# ATmega2560 device description
Architecture: AVR8; Family: megaAVR
Registers are 8-bit, access not given, no defined reset value unless marked. A register's access mark holds for its fields unless they carry their own. Offsets are from the block's base; [hi:lo] are bit positions.

## PORTA — I/O Port
Instances: PORTA 0x00
0x20 PINA — Port A Input Pins
0x21 DDRA — Port A Data Direction Register
0x22 PORTA — Port A Data Register

## PORTB — I/O Port
Instances: PORTB 0x00
0x23 PINB — Port B Input Pins
0x24 DDRB — Port B Data Direction Register
0x25 PORTB — Port B Data Register

## PORTC — I/O Port
Instances: PORTC 0x00
0x26 PINC — Port C Input Pins
0x27 DDRC — Port C Data Direction Register
0x28 PORTC — Port C Data Register

## PORTD — I/O Port
Instances: PORTD 0x00
0x29 PIND — Port D Input Pins
0x2A DDRD — Port D Data Direction Register
0x2B PORTD — Port D Data Register

## PORTE — I/O Port
Instances: PORTE 0x00
0x2C PINE — Input Pins, Port E
0x2D DDRE — Data Direction Register, Port E
0x2E PORTE — Data Register, Port E

## PORTF — I/O Port
Instances: PORTF 0x00
0x2F PINF — Input Pins, Port F
0x30 DDRF — Data Direction Register, Port F
0x31 PORTF — Data Register, Port F

## PORTG — I/O Port
Instances: PORTG 0x00
0x32 PING bits used 5:0 — Input Pins, Port G
0x33 DDRG bits used 5:0 — Data Direction Register, Port G
0x34 PORTG bits used 5:0 — Data Register, Port G

## PORTH — I/O Port
Instances: PORTH 0x00
0x100 PINH — PORT H Input Pins
0x101 DDRH — PORT H Data Direction Register
0x102 PORTH — PORT H Data Register

## PORTJ — I/O Port
Instances: PORTJ 0x00
0x103 PINJ — PORT J Input Pins
0x104 DDRJ — PORT J Data Direction Register
0x105 PORTJ — PORT J Data Register

## PORTK — I/O Port
Instances: PORTK 0x00
0x106 PINK — PORT K Input Pins
0x107 DDRK — PORT K Data Direction Register
0x108 PORTK — PORT K Data Register

## PORTL — I/O Port
Instances: PORTL 0x00
0x109 PINL — PORT L Input Pins
0x10A DDRL — PORT L Data Direction Register
0x10B PORTL — PORT L Data Register

## TC0 (TC8 module) — Timer/Counter, 8-bit
Instances: TC0 0x00
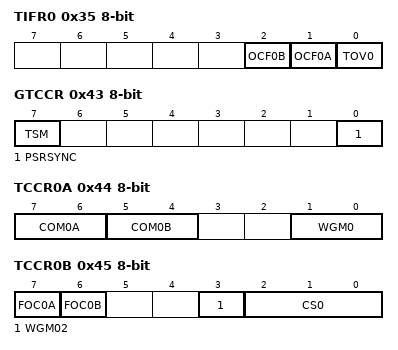
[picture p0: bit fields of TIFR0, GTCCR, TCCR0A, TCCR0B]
0x35 TIFR0 — Timer/Counter0 Interrupt Flag register
  [2] OCF0B — Timer/Counter0 Output Compare Flag 0B
  [1] OCF0A — Timer/Counter0 Output Compare Flag 0A
  [0] TOV0 — Timer/Counter0 Overflow Flag
0x43 GTCCR — General Timer/Counter Control Register
  [7] TSM — Timer/Counter Synchronization Mode
  [0] PSRSYNC — Prescaler Reset Timer/Counter1 and Timer/Counter0
0x44 TCCR0A — Timer/Counter Control Register A
  [7:6] COM0A — Compare Output Mode, Phase Correct PWM Mode
  [5:4] COM0B — Compare Output Mode, Fast PWm
  [1:0] WGM0 — Waveform Generation Mode
0x45 TCCR0B — Timer/Counter Control Register B
  [7] FOC0A — Force Output Compare A
  [6] FOC0B — Force Output Compare B
  [3] WGM02
  [2:0] CS0 — Clock Select
    0=No Clock Source (Stopped); 1=Running, No Prescaling; 2=Running, CLK/8; 3=Running, CLK/64; 4=Running, CLK/256; 5=Running, CLK/1024; 6=Running, ExtClk Tx Falling Edge; 7=Running, ExtClk Tx Rising Edge
0x46 TCNT0 — Timer/Counter0
0x47 OCR0A — Timer/Counter0 Output Compare Register
0x48 OCR0B — Timer/Counter0 Output Compare Register
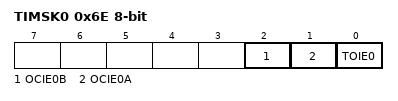
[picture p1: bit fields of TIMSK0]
0x6E TIMSK0 — Timer/Counter0 Interrupt Mask Register
  [2] OCIE0B — Timer/Counter0 Output Compare Match B Interrupt Enable
  [1] OCIE0A — Timer/Counter0 Output Compare Match A Interrupt Enable
  [0] TOIE0 — Timer/Counter0 Overflow Interrupt Enable

## TC2 (TC8_ASYNC module) — Timer/Counter, 8-bit Async
Instances: TC2 0x00
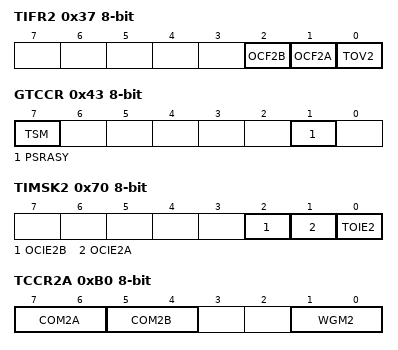
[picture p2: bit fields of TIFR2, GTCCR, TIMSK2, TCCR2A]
0x37 TIFR2 — Timer/Counter Interrupt Flag Register
  [2] OCF2B — Output Compare Flag 2B
  [1] OCF2A — Output Compare Flag 2A
  [0] TOV2 — Timer/Counter2 Overflow Flag
0x43 GTCCR — General Timer Counter Control register
  [7] TSM — Timer/Counter Synchronization Mode
  [1] PSRASY — Prescaler Reset Timer/Counter2
0x70 TIMSK2 — Timer/Counter Interrupt Mask register
  [2] OCIE2B — Timer/Counter2 Output Compare Match B Interrupt Enable
  [1] OCIE2A — Timer/Counter2 Output Compare Match A Interrupt Enable
  [0] TOIE2 — Timer/Counter2 Overflow Interrupt Enable
0xB0 TCCR2A — Timer/Counter2 Control Register A
  [7:6] COM2A — Compare Output Mode bits
  [5:4] COM2B — Compare Output Mode bits
  [1:0] WGM2 — Waveform Genration Mode
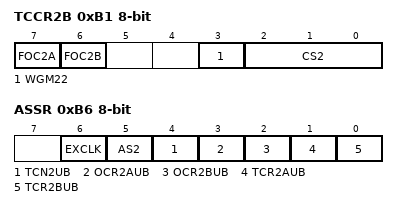
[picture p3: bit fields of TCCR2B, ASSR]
0xB1 TCCR2B — Timer/Counter2 Control Register B
  [7] FOC2A — Force Output Compare A
  [6] FOC2B — Force Output Compare B
  [3] WGM22 — Waveform Generation Mode
  [2:0] CS2 — Clock Select bits
    0=No Clock Source (Stopped); 1=Running, No Prescaling; 2=Running, CLK/8; 3=Running, CLK/32; 4=Running, CLK/64; 5=Running, CLK/128; 6=Running, CLK/256; 7=Running, CLK/1024
0xB2 TCNT2 — Timer/Counter2
0xB3 OCR2A — Timer/Counter2 Output Compare Register A
0xB4 OCR2B — Timer/Counter2 Output Compare Register B
0xB6 ASSR — Asynchronous Status Register
  [6] EXCLK — Enable External Clock Input
  [5] AS2 — Asynchronous Timer/Counter2
  [4] TCN2UB — Timer/Counter2 Update Busy
  [3] OCR2AUB — Output Compare Register2 Update Busy
  [2] OCR2BUB — Output Compare Register 2 Update Busy
  [1] TCR2AUB — Timer/Counter Control Register2 Update Busy
  [0] TCR2BUB — Timer/Counter Control Register2 Update Busy
